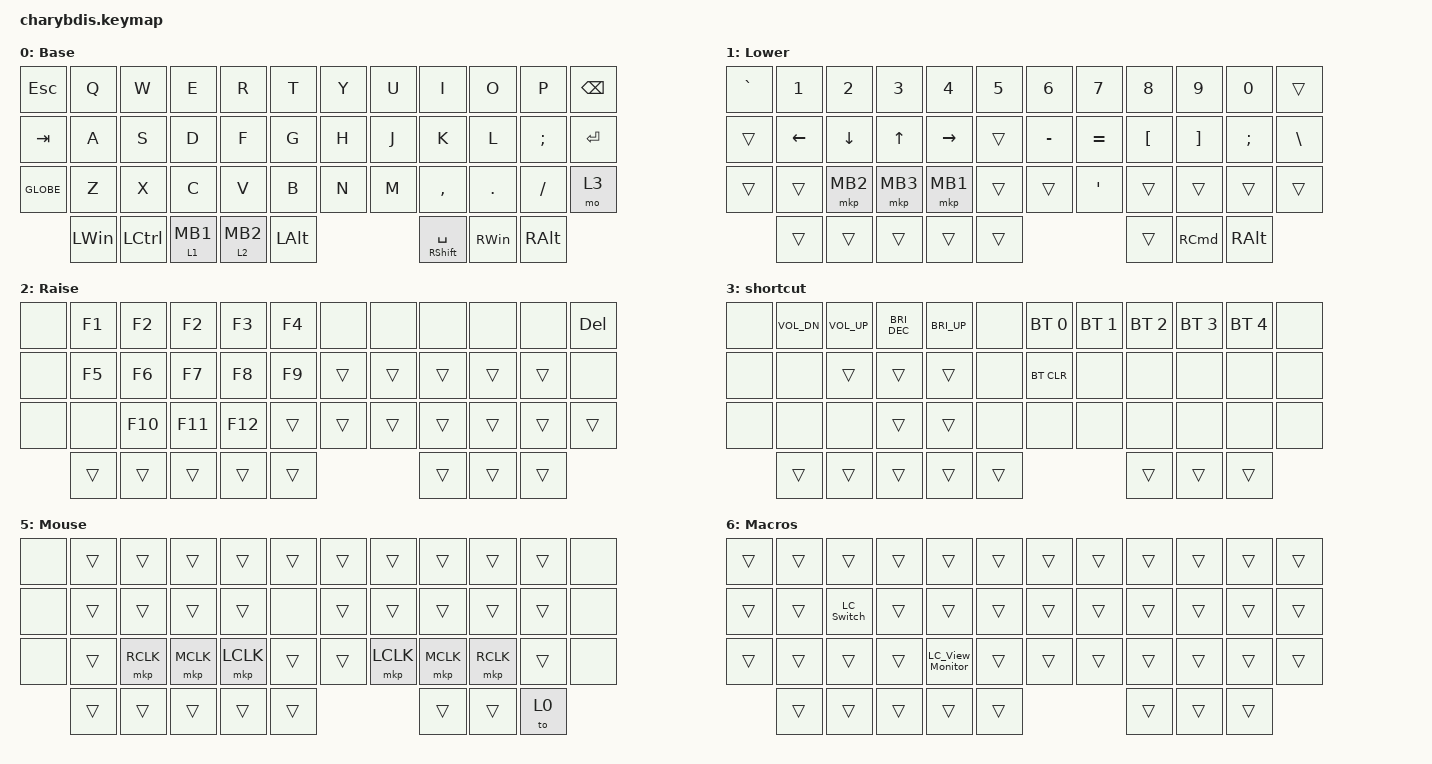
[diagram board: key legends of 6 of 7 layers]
#include <behaviors.dtsi>
#include <dt-bindings/zmk/bt.h>
#include <dt-bindings/zmk/keys.h>
#include <dt-bindings/zmk/mouse.h>

&lt {
    tapping-term-ms = <240>;
    flavor = "balanced";
    quick-tap-ms = <150>;
};

&mt {
    global-quick-tap;
    flavor = "tap-preferred";
    tapping-term-ms = <200>;
};

&sk {
    release-after-ms = <2000>;
    quick-release;
};

/ {
    combos {
        compatible = "zmk,combos";

        GameMode {
            bindings = <&to 4>;
            key-positions = <31 17>;
        };

        NormalMode {
            bindings = <&to 0>;
            key-positions = <30 31>;
        };

        ConstantMouse {
            bindings = <&to 5>;
            key-positions = <31 9>;
        };
    };

    behaviors {
        hm: homerow_mods {
            compatible = "zmk,behavior-hold-tap";
            label = "HOMEROW_MODS";
            bindings = <&kp>, <&kp>;

            #binding-cells = <2>;
            tapping-term-ms = <200>;
            quick-tap-ms = <180>;
            flavor = "tap-preferred";
        };

        ltq: ltq {
            compatible = "zmk,behavior-hold-tap";
            label = "LTQ";
            bindings = <&mo>, <&kp>;

            #binding-cells = <2>;
            tapping-term-ms = <200>;
            quick-tap-ms = <180>;
        };

        as: auto_shift {
            compatible = "zmk,behavior-hold-tap";
            label = "AUTO_SHIFT";
            bindings = <&kp>, <&kp>;

            #binding-cells = <2>;
            tapping-term-ms = <135>;
            quick-tap-ms = <0>;
        };

        mkm: mkm {
            compatible = "zmk,behavior-hold-tap";
            label = "MKM";
            bindings = <&mo>, <&mkp>;

            #binding-cells = <2>;
            tapping-term-ms = <200>;
            quick-tap-ms = <100>;
        };
    };

    macros {
        LC_Switch: LC_Switch {
            compatible = "zmk,behavior-macro";
            #binding-cells = <0>;
            bindings = <&kp S &kp W &kp I &kp T &kp C &kp H &kp RETURN>;
            label = "LC_SWITCH";
        };

        LC_View_Monitor: LC_View_Monitor {
            compatible = "zmk,behavior-macro";
            #binding-cells = <0>;
            bindings = <&kp V &kp I &kp E &kp W &kp SPACE &kp M &kp O &kp N &kp I &kp T &kp O &kp R &kp RETURN>;
            label = "LC_VIEW_MONITOR";
        };
    };

    keymap {
        compatible = "zmk,keymap";

        Base {
            label = "Base";
            bindings = <
&kp ESC    &kp Q         &kp W      &kp E       &kp R       &kp T         &kp Y  &kp U  &kp I                  &kp O       &kp P          &kp BACKSPACE
&kp TAB    &kp A         &kp S      &kp D       &kp F       &kp G         &kp H  &kp J  &kp K                  &kp L       &kp SEMI       &kp ENTER
&kp GLOBE  &kp Z         &kp X      &kp C       &kp V       &kp B         &kp N  &kp M  &kp COMMA              &kp PERIOD  &kp SLASH      &mo 3
           &kp LEFT_WIN  &kp LCTRL  &mkm 1 MB1  &mkm 2 MB2  &kp LEFT_ALT                &mt RIGHT_SHIFT SPACE  &kp RWIN    &kp RIGHT_ALT
            >;
        };

        Lower {
            label = "Lower";
            bindings = <
&kp GRAVE  &kp NUMBER_1  &kp NUMBER_2  &kp NUMBER_3  &kp NUMBER_4  &kp NUMBER_5  &kp NUMBER_6  &kp N7     &kp N8            &kp N9             &kp NUMBER_0   &trans
&trans     &kp LEFT      &kp DOWN      &kp UP        &kp RIGHT     &trans        &kp MINUS     &kp EQUAL  &kp LEFT_BRACKET  &kp RIGHT_BRACKET  &kp SEMICOLON  &kp BSLH
&trans     &trans        &mkp MB2      &mkp MB3      &mkp MB1      &trans        &trans        &kp SQT    &trans            &trans             &trans         &trans
           &trans        &trans        &trans        &trans        &trans                                 &trans            &kp RCMD           &kp RALT
            >;
        };

        Raise {
            label = "Raise";
            bindings = <
&none  &kp F1  &kp F2   &kp F2   &kp F3   &kp F4  &none   &none   &none   &none   &none   &kp DELETE
&none  &kp F5  &kp F6   &kp F7   &kp F8   &kp F9  &trans  &trans  &trans  &trans  &trans  &none
&none  &none   &kp F10  &kp F11  &kp F12  &trans  &trans  &trans  &trans  &trans  &trans  &trans
       &trans  &trans   &trans   &trans   &trans                  &trans  &trans  &trans
            >;
        };

        Shortcut {
            label = "shortcut";
            bindings = <
&none  &kp C_VOL_DN  &kp C_VOL_UP  &kp C_BRI_DEC  &kp C_BRI_UP  &none   &bt BT_SEL 0  &bt BT_SEL 1  &bt BT_SEL 2  &bt BT_SEL 3  &bt BT_SEL 4  &none
&none  &none         &trans        &trans         &trans        &none   &bt BT_CLR    &none         &none         &none         &none         &none
&none  &none         &none         &trans         &trans        &none   &none         &none         &none         &none         &none         &none
       &trans        &trans        &trans         &trans        &trans                              &trans        &trans        &trans
            >;
        };

        Game {
            label = "Game";
            bindings = <
&kp ESC  &trans          &kp Q         &kp W      &kp E         &kp R         &kp T  &kp Y     &kp U     &trans           &none   &kp BACKSPACE
&kp TAB  &kp LEFT_SHIFT  &kp A         &kp S      &kp D         &kp F         &kp G  &mkp MB1  &mkp MB2  &kp RIGHT_SHIFT  &none   &kp RETURN
&none    &kp LCTRL       &kp Z         &kp X      &kp C         &kp V         &kp B  &kp N1    &kp N2    &kp N3           &kp N4  &kp N5
         &kp NUMBER_2    &kp NUMBER_1  &kp SPACE  &kp NUMBER_3  &kp NUMBER_4                   &mo 6     &none
            >;
        };

        Mouse {
            bindings = <
&none  &trans  &trans     &trans     &trans     &trans  &trans  &trans     &trans     &trans     &trans  &none
&none  &trans  &trans     &trans     &trans     &none   &trans  &trans     &trans     &trans     &trans  &none
&none  &trans  &mkp RCLK  &mkp MCLK  &mkp LCLK  &trans  &trans  &mkp LCLK  &mkp MCLK  &mkp RCLK  &trans  &none
       &trans  &trans     &trans     &trans     &trans                     &trans     &trans     &to 0
            >;
        };

        Macros {
            bindings = <
&trans  &trans  &trans      &trans  &trans            &trans  &trans  &trans  &trans  &trans  &trans  &trans
&trans  &trans  &LC_Switch  &trans  &trans            &trans  &trans  &trans  &trans  &trans  &trans  &trans
&trans  &trans  &trans      &trans  &LC_View_Monitor  &trans  &trans  &trans  &trans  &trans  &trans  &trans
        &trans  &trans      &trans  &trans            &trans                  &trans  &trans  &trans
            >;
        };
    };
};
